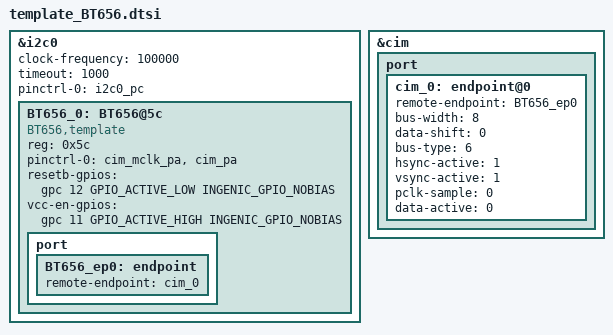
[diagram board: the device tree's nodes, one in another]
&i2c0 {
	status = "okay";
	clock-frequency = <100000>;
	timeout = <1000>;
	pinctrl-names = "default";
	pinctrl-0 = <&i2c0_pc>;

	BT656_0:BT656@5c {
		status = "ok";
		compatible = "BT656,template";
		reg = <0x5c>;
		pinctrl-names = "default";
		pinctrl-0 = <&cim_mclk_pa>, <&cim_pa>;

		resetb-gpios = <&gpc 12 GPIO_ACTIVE_LOW INGENIC_GPIO_NOBIAS>;
		vcc-en-gpios = <&gpc 11 GPIO_ACTIVE_HIGH INGENIC_GPIO_NOBIAS>;

		port {
			BT656_ep0:endpoint {
				remote-endpoint = <&cim_0>;
			};
		};
	};
};

&cim {
	status = "okay";
	port {
		cim_0: endpoint@0 {
			remote-endpoint = <&BT656_ep0>;
			bus-width = <8>;
			data-shift = <0>;
			bus-type = <6>;

			hsync-active = <1>;
			vsync-active = <1>;
			pclk-sample = <0>;
			data-active = <0>;
		};
	};
};




